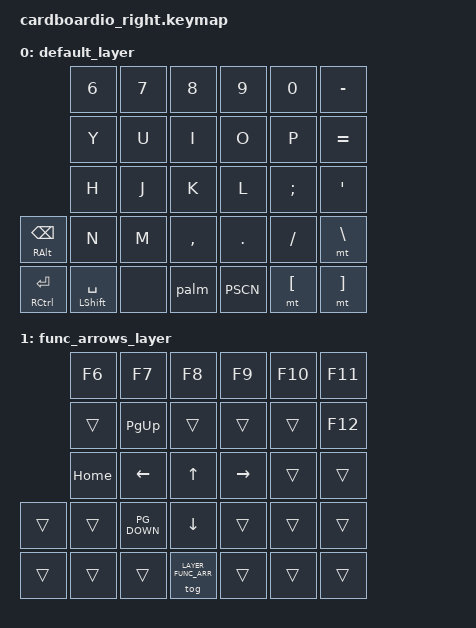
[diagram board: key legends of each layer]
/*
 * Copyright (c) 2020 The ZMK Contributors
 *
 * SPDX-License-Identifier: MIT
 */

#include <behaviors.dtsi>
#include <dt-bindings/zmk/keys.h>
#include <dt-bindings/zmk/bt.h>

#define LAYER_DEFAULT 0
#define LAYER_FUNC_ARR 1

/ {
        behaviors {
                palm: palm_hold_tap {
                        compatible = "zmk,behavior-hold-tap";
                        label = "PALM_HOLD_TAP";
                        binding-cells = <0>;
                        flavor = "balanced";
                        tapping-term-ms = <200>;
                        quick-tap-ms = <200>;
                        bindings = <&tog LAYER_FUNC_ARR>, <&mo LAYER_FUNC_ARR>;
                };

        };

        keymap {
                compatible = "zmk,keymap";

                default_layer {
/* QWERTY
 *             .------------------------------------------
 *             |   6  |   7  |   8  |   9  |   0  |   -  |
 *             |------+------+------+------+------+------+
 *             |   Y  |   U  |   I  |   O  |   P  |   =  |
 *             |------+------+------+------+------+------+
 *             |   H  |   J  |   K  |   L  |   ;  |   '  |
 *             |------+------+------+------+------+------+
 * +------+    |   N  |   M  |   ,  |   .  |   /  |   \  |
 * | ⌫/Alt|    +------+------+------+------+------+------+
 * +------+------+------+           |PrtScn|   [  |   ]  |  
 * | ↵/Ctl|  ␣/⇧ |      |           +------+------+------+
 * +------+------+------+
 *                           +------+
 *                           |  L1  |
 *                           +------+
 */
                        bindings = <
              &kp  N6       &kp  N7       &kp  N8       &kp  N9       &kp  N0       &kp  MINUS
              &kp  Y        &kp  U        &kp  I        &kp  O        &kp  P        &kp  EQUAL
              &kp  H        &kp  J        &kp  K        &kp  L        &kp  SEMI     &kp  APOS
&mt RALT BSPC &kp  N        &kp  M        &kp  COMMA    &kp  PERIOD   &kp  SLASH    &mt  BACKSLASH
&mt RCTRL RET &mt LSHIFT SPACE &none      &palm         &kp  PSCN     &mt  LBKT     &mt  RBKT
                        >;

                        sensor-bindings = <
                                &inc_dep_kp LEFT RIGHT
                        >;
                };

                func_arrows_layer {
/* Function row and alternate arrow keys
 *             .------------------------------------------
 *             |  F6  |  F7  |  F8  |  F9  |  F10 |  F11 |
 *             |------+------+------+------+------+------+
 *             |      | PgUp |      |      |      |  F12 |
 *             |------+------+------+------+------+------+
 *             | Home |  <-  |   ^  |  ->  |  End |      |
 *             |------+------+------+------+------+------+
 * +------+    |      | PgDn |   v  |      |      |      |
 * |      |    +------+------+------+------+------+------+
 * +------+------+------+           |      |      |      |  
 * |      |      |      |           +------+------+------+
 * +------+------+------+
 *                           +------+
 *                           | -L1  |
 *                           +------+
 */
                        bindings = <
              &kp  F6       &kp  F7       &kp  F8       &kp  F9       &kp  F10      &kp  F11
              &trans        &kp  PG_UP    &trans        &trans        &trans        &kp  F12
              &kp  HOME     &kp  LEFT     &kp  UP       &kp  RIGHT    &trans        &trans
&trans        &trans        &kp  PG_DOWN  &kp  DOWN     &trans        &trans        &trans
&trans        &trans        &trans        &tog LAYER_FUNC_ARR         &trans        &trans     &trans
                        >;

                        sensor_bindings = <
                                &inc_dep_kp C_AC_SCROLL_LEFT C_AC_SCROLL_RIGHT
                        >;
                };
        };
};

